# STM32G431xx register map
File version: 1.9
CPU: CM4 r0p1, little endian, MPU, FPU, 4 interrupt priority bits
Registers are 32-bit, read-write, reset 0x0 unless marked. A register's access mark holds for its fields unless they carry their own. Offsets are from the block's base; [hi:lo] are bit positions; {n}, {i} and the like mark numbered series.

## PWR — Power control
Base 0x40007000
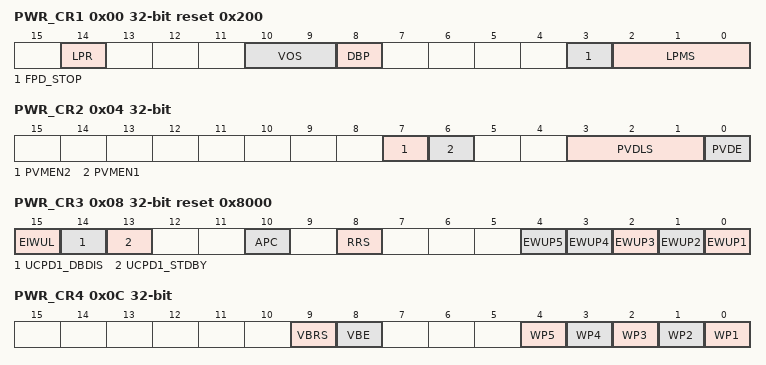
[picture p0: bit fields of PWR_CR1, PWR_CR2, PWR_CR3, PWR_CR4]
0x00 PWR_CR1 reset 0x200 — Power control register 1
  [14] LPR — Low-power run When this bit is set, the regulator is switched from main mode (MR) to low-power mode (LPR).
  [10:9] VOS — Voltage scaling range selection
    0=Cannot be written (forbidden by hardware); 1=Range 1; 2=Range 2; 3=Cannot be written (forbidden by hardware)
  [8] DBP — Disable backup domain write protection In reset state, the RTC and backup registers are protected against parasitic write access. This bit must be set to enable write access to these registers.
    0=Access to RTC and Backup registers disabled; 1=Access to RTC and Backup registers enabled
  [3] FPD_STOP
  [2:0] LPMS — Low-power mode selection These bits select the low-power mode entered when CPU enters the deepsleep mode. 1xx: Shutdown mode Note: In Standby mode, SRAM2 can be preserved or not, depending on RRS bit configuration in PWR_CR3.
    0=Stop 0 mode; 1=Stop 1 mode; 3=Standby mode
0x04 PWR_CR2 — Power control register 2
  [7] PVMEN2 — Peripheral voltage monitoring 4 enable: V<sub>DDA</sub> vs. DAC 1MSPS /DAC 15MSPS min voltage.
    0=PVM2 (V<sub>DDA</sub> monitoring vs. 1.8 V threshold) disable.; 1=PVM2 (V<sub>DDA</sub> monitoring vs. 1.8 V threshold) enable.
  [6] PVMEN1 — Peripheral voltage monitoring 3 enable: V<sub>DDA</sub> vs. ADC/COMP min voltage 1.62V
    0=PVM1 (V<sub>DDA</sub> monitoring vs. 1.62V threshold) disable.; 1=PVM1 (V<sub>DDA</sub> monitoring vs. 1.62V threshold) enable.
  [3:1] PVDLS — Programmable voltage detector level selection. These bits select the PVD falling threshold: Note: These bits are write-protected when the PVDL bit is set in the SYSCFG_CFGR2 register. The protection can be reset only by a system reset.
    {v}=V<sub>PVD{v}</sub> PVD threshold {v} (v=0..6); 7=External input analog voltage PVD_IN (compared internally to V<sub>REFINT</sub>)
  [0] PVDE — Programmable voltage detector enable Note: This bit is write-protected when the PVDL bit is set in the SYSCFG_CFGR2 register. The protection can be reset only by a system reset.
    0=Programmable voltage detector disable; 1=Programmable voltage detector enable
0x08 PWR_CR3 reset 0x8000 — Power control register 3
  [15] EIWUL — Enable internal wakeup line
    0=Internal wakeup line disable; 1=Internal wakeup line enable
  [14] UCPD1_DBDIS — USB Type-C and Power Delivery Dead Battery disable. After exiting reset, the USB Type-C “dead battery” behavior is enabled, which may have a pull-down effect on CC1 and CC2 pins. It is recommended to disable it in all cases, either to stop this pull-down or to hand over control to the UCPD1 (which should therefore be initialized before doing the disable).
    0=Enable USB Type-C dead battery pull-down behavior on UCPD1_CC1 and UCPD1_CC2 pins; 1=Disable USB Type-C dead battery pull-down behavior on UCPD1_CC1 and UCPD1_CC2 pins
  [13] UCPD1_STDBY — UCPD1_STDBY USB Type-C and Power Delivery standby mode.
    0=Write ‘0’ immediately after standby exit when using UCPD1, (and before writing any UCPD1 registers); 1=Write ‘1’ just before entering standby when using UCPD1
  [10] APC — Apply pull-up and pull-down configuration When this bit is set, the I/O pull-up and pull-down configurations defined in the PWR_PUCRx and PWR_PDCRx registers are applied. When this bit is cleared, the PWR_PUCRx and PWR_PDCRx registers are not applied to the I/Os.
  [8] RRS — SRAM2 retention in Standby mode
    0=SRAM2 is powered off in Standby mode (SRAM2 content is lost); 1=SRAM2 is powered by the low-power regulator in Standby mode (SRAM2 content is kept)
  [4] EWUP5 — Enable Wakeup pin WKUP5 When this bit is set, the external wakeup pin WKUP5 is enabled and triggers a wakeup from Standby or Shutdown event when a rising or a falling edge occurs.The active edge is configured via the WP5 bit in the PWR_CR4 register.
  [n-1] EWUP{n} (n=1..4) — Enable Wakeup pin WKUP{n} When this bit is set, the external wakeup pin WKUP{n} is enabled and triggers a wakeup from Standby or Shutdown event when a rising or a falling edge occurs. The active edge is configured via the WP{n} bit in the PWR_CR4 register.
0x0C PWR_CR4 — Power control register 4
  [9] VBRS — V<sub>BAT</sub> battery charging resistor selection
    0=Charge V<sub>BAT</sub> through a 5 kOhms resistor; 1=Charge V<sub>BAT</sub> through a 1.5 kOhms resistor
  [8] VBE — V<sub>BAT</sub> battery charging enable
    0=V<sub>BAT</sub> battery charging disable; 1=V<sub>BAT</sub> battery charging enable
  [n-1] WP{n} (n=1..5) — Wakeup pin WKUP{n} polarity This bit defines the polarity used for an event detection on external wake-up pin, WKUP{n}
    0=Detection on high level (rising edge); 1=Detection on low level (falling edge)
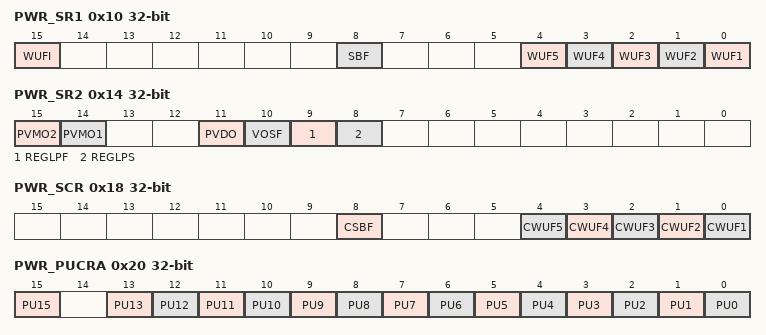
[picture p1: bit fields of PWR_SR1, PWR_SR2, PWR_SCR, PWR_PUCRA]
0x10 PWR_SR1 ro — Power status register 1
  [15] WUFI — Wakeup flag internal This bit is set when a wakeup is detected on the internal wakeup line. It is cleared when all internal wakeup sources are cleared.
  [8] SBF — Standby flag This bit is set by hardware when the device enters the Standby mode and is cleared by setting the CSBF bit in the PWR_SCR register, or by a power-on reset. It is not cleared by the system reset.
    0=The device did not enter the Standby mode; 1=The device entered the Standby mode
  [4] WUF5 — Wakeup flag 5 This bit is set when a wakeup event is detected on wakeup pin, WKUP5. It is cleared by writing ‘1’ in the CWUF5 bit of the PWR_SCR register.
  [3] WUF4 — Wakeup flag 4 This bit is set when a wakeup event is detected on wakeup pin,WKUP4. It is cleared by writing ‘1’ in the CWUF4 bit of the PWR_SCR register.
  [2] WUF3 — Wakeup flag 3 This bit is set when a wakeup event is detected on wakeup pin, WKUP3. It is cleared by writing ‘1’ in the CWUF3 bit of the PWR_SCR register.
  [1] WUF2 — Wakeup flag 2 This bit is set when a wakeup event is detected on wakeup pin, WKUP2. It is cleared by writing ‘1’ in the CWUF2 bit of the PWR_SCR register.
  [0] WUF1 — Wakeup flag 1 This bit is set when a wakeup event is detected on wakeup pin, WKUP1. It is cleared by writing ‘1’ in the CWUF1 bit of the PWR_SCR register.
0x14 PWR_SR2 ro — Power status register 2
  [15] PVMO2 — Peripheral voltage monitoring output: V<sub>DDA</sub> vs. 1.8 V Note: PVMO2 is cleared when PVM2 is disabled (PVME = 0). After enabling PVM2, the PVM2 output is valid after the PVM2 wakeup time.
    0=V<sub>DDA</sub> voltage is above PVM2 threshold (around 1.8 V); 1=V<sub>DDA</sub> voltage is below PVM2 threshold (around 1.8 V)
  [14] PVMO1 — Peripheral voltage monitoring output: V<sub>DDA</sub> vs. 1.62 V Note: PVMO1 is cleared when PVM1 is disabled (PVME = 0). After enabling PVM1, the PVM1 output is valid after the PVM1 wakeup time.
    0=V<sub>DDA</sub> voltage is above PVM1 threshold (around 1.62 V); 1=V<sub>DDA</sub> voltage is below PVM1 threshold (around 1.62 V)
  [11] PVDO — Programmable voltage detector output
    0=V<sub>DD</sub> is above the selected PVD threshold; 1=V<sub>DD</sub> is below the selected PVD threshold
  [10] VOSF — Voltage scaling flag A delay is required for the internal regulator to be ready after the voltage scaling has been changed. VOSF indicates that the regulator reached the voltage level defined with VOS bits of the PWR_CR1 register.
    0=The regulator is ready in the selected voltage range; 1=The regulator output voltage is changing to the required voltage level
  [9] REGLPF — Low-power regulator flag This bit is set by hardware when the MCU is in Low-power run mode. When the MCU exits the Low-power run mode, this bit remains at 1 until the regulator is ready in main mode. A polling on this bit must be done before increasing the product frequency. This bit is cleared by hardware when the regulator is ready.
    0=The regulator is ready in main mode (MR); 1=The regulator is in low-power mode (LPR)
  [8] REGLPS — Low-power regulator started This bit provides the information whether the low-power regulator is ready after a power-on reset or a Standby/Shutdown. If the Standby mode is entered while REGLPS bit is still cleared, the wakeup from Standby mode time may be increased.
    0=The low-power regulator is not ready; 1=The low-power regulator is ready
0x18 PWR_SCR wo — Power status clear register
  [8] CSBF — Clear standby flag Setting this bit clears the SBF flag in the PWR_SR1 register.
  [n-1] CWUF{n} (n=1..5) — Clear wakeup flag {n} Setting this bit clears the WUF{n} flag in the PWR_SR1 register.
0x20 PWR_PUCRA — Power Port A pull-up control register
  [15] PU15 — Port A pull-up bit 15 When set, this bit activates the pull-up on PA[15] when APC bit is set in PWR_CR3 register. The pull-up is not activated if the corresponding PD15 bit is also set.
  [n] PU{n} (n=0..13) — Port A pull-up bit y (y=0..13) When set, this bit activates the pull-up on PA[y] when APC bit is set in PWR_CR3 register. The pull-up is not activated if the corresponding PDy bit is also set.
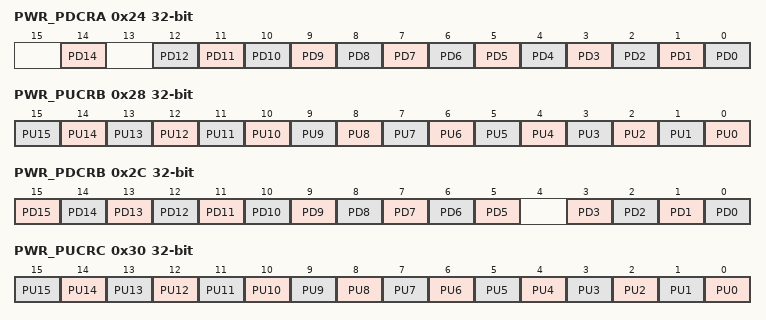
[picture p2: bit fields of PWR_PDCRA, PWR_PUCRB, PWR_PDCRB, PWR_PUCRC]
0x24 PWR_PDCRA — Power Port A pull-down control register
  [14] PD14 — Port A pull-down bit 14 When set, this bit activates the pull-down on PA[14] when APC bit is set in PWR_CR3 register.
  [n] PD{n} (n=0..12) — Port A pull-down bit y (y=0..12) When set, this bit activates the pull-down on PA[y] when APC bit is set in PWR_CR3 register.
0x28 PWR_PUCRB — Power Port B pull-up control register
  [n] PU{n} (n=0..15) — Port B pull-up bit y (y=0..15) When set, this bit activates the pull-up on PB[y] when APC bit is set in PWR_CR3 register. The pull-up is not activated if the corresponding PDy bit is also set.
0x2C PWR_PDCRB — Power Port B pull-down control register
  [n] PD{n} (n=5..15) — Port B pull-down bit y (y=5..15) When set, this bit activates the pull-down on PB[y] when APC bit is set in PWR_CR3 register.
  [n] PD{n} (n=0..3) — Port B pull-down bit y (y=0..3) When set, this bit activates the pull-down on PB[y] when APC bit is set in PWR_CR3 register.
0x30 PWR_PUCRC — Power Port C pull-up control register
  [n] PU{n} (n=0..15) — Port C pull-up bit y (y=0..15) When set, this bit activates the pull-up on PC[y] when APC bit is set in PWR_CR3 register. The pull-up is not activated if the corresponding PDy bit is also set.
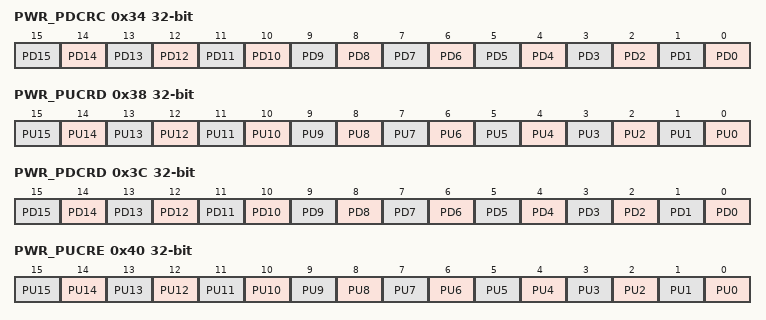
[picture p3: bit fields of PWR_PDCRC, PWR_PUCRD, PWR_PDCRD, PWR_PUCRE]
0x34 PWR_PDCRC — Power Port C pull-down control register
  [n] PD{n} (n=0..15) — Port C pull-down bit y (y=0..15) When set, this bit activates the pull-down on PC[y] when APC bit is set in PWR_CR3 register.
0x38 PWR_PUCRD — Power Port D pull-up control register
  [n] PU{n} (n=0..15) — Port D pull-up bit y (y=0..15) When set, this bit activates the pull-up on PD[y] when APC bit is set in PWR_CR3 register. The pull-up is not activated if the corresponding PDy bit is also set.
0x3C PWR_PDCRD — Power Port D pull-down control register
  [n] PD{n} (n=0..15) — Port D pull-down bit y (y=0..15) When set, this bit activates the pull-down on PD[y] when APC bit is set in PWR_CR3 register.
0x40 PWR_PUCRE — Power Port E pull-up control register
  [n] PU{n} (n=0..15) — Port E pull-up bit y (y=0..15) When set, this bit activates the pull-up on PE[y] when APC bit is set in PWR_CR3 register. The pull-up is not activated if the corresponding PDy bit is also set.
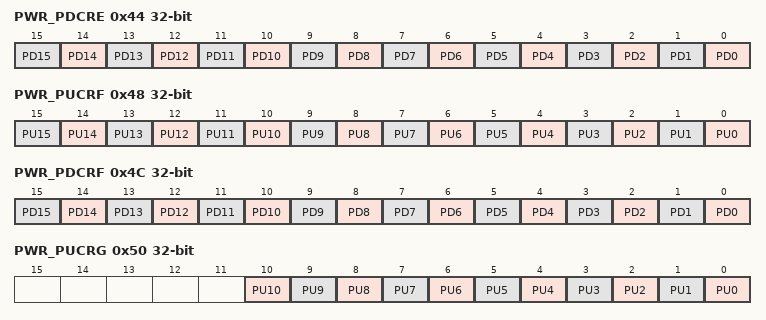
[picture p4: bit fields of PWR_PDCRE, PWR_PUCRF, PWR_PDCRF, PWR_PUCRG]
0x44 PWR_PDCRE — Power Port E pull-down control register
  [n] PD{n} (n=0..15) — Port E pull-down bit y (y=0..15) When set, this bit activates the pull-down on PE[y] when APC bit is set in PWR_CR3 register.
0x48 PWR_PUCRF — Power Port F pull-up control register
  [n] PU{n} (n=0..15) — Port F pull-up bit y (y=0..15) When set, this bit activates the pull-up on PF[y] when APC bit is set in PWR_CR3 register. The pull-up is not activated if the corresponding PDy bit is also set.
0x4C PWR_PDCRF — Power Port F pull-down control register
  [n] PD{n} (n=0..15) — Port F pull-down bit y (y=0..15) When set, this bit activates the pull-down on PF[y] when APC bit is set in PWR_CR3 register.
0x50 PWR_PUCRG — Power Port G pull-up control register
  [n] PU{n} (n=0..10) — Port G pull-up bit y (y=0..10) When set, this bit activates the pull-up on PG[y] when APC bit is set in PWR_CR3 register. The pull-up is not activated if the corresponding PDy bit is also set.
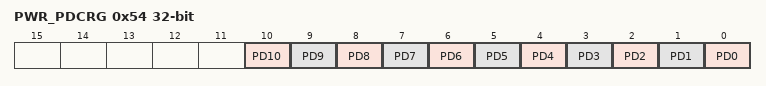
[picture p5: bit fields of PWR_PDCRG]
0x54 PWR_PDCRG — Power Port G pull-down control register
  [n] PD{n} (n=0..10) — Port G pull-down bit y (y=0..10) When set, this bit activates the pull-down on PG[y] when APC bit is set in PWR_CR3 register.
0x80 PWR_CR5 reset 0x100 — Power control register
  [8] R1MODE — Main regular range 1 mode This bit is only valid for the main regulator in range 1 and has no effect on range 2. It is recommended to reset this bit when the system frequency is greater than 150 MHz. Refer to
    0=Main regulator in range 1 boost mode; 1=Main regulator in range 1 normal mode
